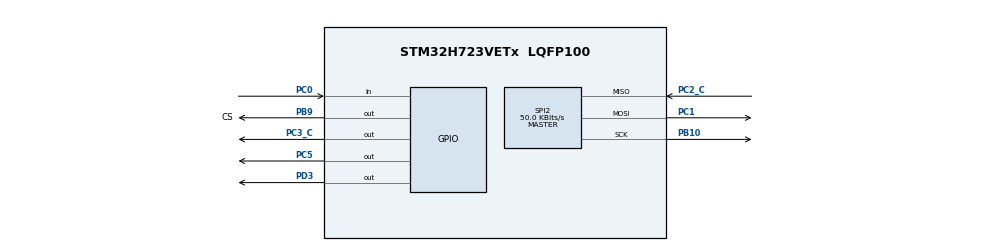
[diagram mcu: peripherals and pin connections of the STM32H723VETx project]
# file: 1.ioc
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CORTEX_M7.default_mode_Activation=1
Mcu.Family=STM32H7
Mcu.Name=STM32H723VETx
Mcu.Package=LQFP100
NVIC.PriorityGroup=NVIC_PRIORITYGROUP_4
NVIC.SPI2_IRQn=true\:0\:0\:false\:false\:true\:true\:true\:true
PB10.GPIO_PuPd=GPIO_PULLDOWN
PB10.GPIO_Speed=GPIO_SPEED_FREQ_HIGH
PB10.Mode=Full_Duplex_Master
PB10.Signal=SPI2_SCK
PB9.GPIO_Label=CS
PB9.GPIO_ModeDefaultOutputPP=GPIO_MODE_OUTPUT_PP
PB9.GPIO_PuPd=GPIO_PULLDOWN
PB9.GPIO_Speed=GPIO_SPEED_FREQ_HIGH
PB9.PinState=GPIO_PIN_SET
PB9.Signal=GPIO_Output
PC0.Signal=GPIO_Input
PC1.GPIO_PuPd=GPIO_PULLDOWN
PC1.GPIO_Speed=GPIO_SPEED_FREQ_HIGH
PC1.Mode=Full_Duplex_Master
PC1.Signal=SPI2_MOSI
PC2_C.GPIO_PuPd=GPIO_PULLUP
PC2_C.GPIO_Speed=GPIO_SPEED_FREQ_HIGH
PC2_C.Mode=Full_Duplex_Master
PC2_C.Signal=SPI2_MISO
PC3_C.GPIO_PuPd=GPIO_PULLDOWN
PC3_C.Signal=GPIO_Output
PC5.GPIO_ModeDefaultOutputPP=GPIO_MODE_OUTPUT_PP
PC5.GPIO_PuPd=GPIO_PULLDOWN
PC5.Signal=GPIO_Output
PD3.PinState=GPIO_PIN_SET
PD3.Signal=GPIO_Output
PH0-OSC_IN.Mode=HSE-External-Oscillator
PH0-OSC_IN.Signal=RCC_OSC_IN
PH1-OSC_OUT.Mode=HSE-External-Oscillator
PH1-OSC_OUT.Signal=RCC_OSC_OUT
ProjectManager.HeapSize=0x200
ProjectManager.StackSize=0x400
ProjectManager.TargetToolchain=MDK-ARM V5.32
RCC.ADCFreq_Value=6400000
RCC.APB1Freq_Value=42500000
RCC.APB2Freq_Value=42500000
RCC.APB3Freq_Value=42500000
RCC.APB4Freq_Value=42500000
RCC.CortexFreq_Value=340000000
RCC.DIVM1=1
RCC.DIVM2=6
RCC.DIVN1=42
RCC.DIVN2=120
RCC.DIVP1=1
RCC.DIVP2=25
RCC.HCLKFreq_Value=42500000
RCC.HPRE=RCC_HCLK_DIV8
RCC.HSE_VALUE=8000000
RCC.PLL3FRACN=0
RCC.PLLFRACN=4096
RCC.PLLSourceVirtual=RCC_PLLSOURCE_HSE
RCC.SPI123CLockSelection=RCC_SPI123CLKSOURCE_PLL2
RCC.SYSCLKFreq_VALUE=340000000
RCC.SYSCLKSource=RCC_SYSCLKSOURCE_PLLCLK
RCC.USBFreq_Value=170000000
SPI2.BaudRatePrescaler=SPI_BAUDRATEPRESCALER_128
SPI2.CLKPhase=SPI_PHASE_2EDGE
SPI2.CLKPolarity=SPI_POLARITY_LOW
SPI2.CRCCalculation=SPI_CRCCALCULATION_DISABLE
SPI2.CalculateBaudRate=50.0 KBits/s
SPI2.DataSize=SPI_DATASIZE_8BIT
SPI2.Direction=SPI_DIRECTION_2LINES
SPI2.Mode=SPI_MODE_MASTER
SPI2.NSSPMode=SPI_NSS_PULSE_ENABLE
SPI2.VirtualType=VM_MASTER
board=custom

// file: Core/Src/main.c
/* USER CODE BEGIN Header */
/**
  ******************************************************************************
  * @file           : main.c
  * @brief          : Main program body
  ******************************************************************************
  * @attention
  *
  * Copyright (c) 2022 STMicroelectronics.
  * All rights reserved.
  *
  * This software is licensed under terms that can be found in the LICENSE file
  * in the root directory of this software component.
  * If no LICENSE file comes with this software, it is provided AS-IS.
  *
  ******************************************************************************
  */
/* USER CODE END Header */
#include "main.h"

/* USER CODE BEGIN Includes */
#include "CDD_L9963_drv_interface.h"
/* USER CODE END Includes */

SPI_HandleTypeDef hspi2;

void SystemClock_Config(void);
static void MPU_Config(void);
static void MX_GPIO_Init(void);
static void MX_SPI2_Init(void);

int main(void)
{

  /* MPU Configuration--------------------------------------------------------*/
  MPU_Config();

  /* MCU Configuration--------------------------------------------------------*/

  /* Reset of all peripherals, Initializes the Flash interface and the Systick. */
  HAL_Init();

  /* Configure the system clock */
  SystemClock_Config();

  /* Initialize all configured peripherals */
  MX_GPIO_Init();
  MX_SPI2_Init();
  /* USER CODE BEGIN 2 */
	HAL_GPIO_WritePin(GPIOB, GPIO_PIN_10, GPIO_PIN_RESET);

  /* USER CODE END 2 */

  /* Infinite loop */
  /* USER CODE BEGIN WHILE */
	uint8_t t = 0;
  L9963_Test_Init();
	//uint8_t return_code = true;
	//uint8 res = true;

	//L9963_SPI_Rx_Inst_t  *spi_rx;
	//spi_rx = 0;
	//uint8_t op_code[1] = {0xff};
	//HAL_GPIO_WritePin(GPIOB, GPIO_PIN_9, GPIO_PIN_RESET);

	uint8_t spi_mosi[5];

  while (1)
  {
		//uint8_t res = true;
    /* USER CODE END WHILE */

    /* USER CODE BEGIN 3 */

		//GCDD_L9963_CellVol_Burst_Read();
		//L9963_SPI_Rx_Inst_t spi_rx_t;

		//L9963_SPI_CS_SELECT;

		//HAL_SPI_Transmit(&hspi2,&t,1,100);

		//L9963_SPI_CS_UNSELECT;

//		//	L9963_SPI_CS_SELECT;
//
//		//res = 	HAL_SPI_TransmitReceive( &hspi2, &spi_mosi[0], (((uint8 *) spi_rx) ), 5,  100);
//
//	//	GCDD_L9963_TxData(&spi_mosi[0], (((uint8 *) spi_rx) ), 5);
//
//		L9963_SPI_CS_UNSELECT;
//	HAL_Delay(319); /*Total Delay time need to be 219us */
//	L9963_SPI_CS_SELECT;
//		//	HAL_SPI_TransmitReceive( &hspi2, &spi_mosi[0], (((uint8 *) spi_rx) ), 5,  100);
//		HAL_SPI_Transmit(&hspi2, spi_mosi,5,100);
//
//		L9963_SPI_CS_UNSELECT;
//	HAL_Delay(319);
//	spi_mosi[0] = 0xC0; /*first 24 bit is reseved*/
//	spi_mosi[1] = 0x04;
//	spi_mosi[2] = 0x0F;
//	spi_mosi[3] = 0x00;
//	spi_mosi[4] = 0x28;
//
//		L9963_SPI_CS_SELECT;
//		//	HAL_SPI_TransmitReceive( &hspi2, &spi_mosi[0], (((uint8 *) spi_rx) ), 5,  100);
//			HAL_SPI_Transmit(&hspi2, spi_mosi,5,100);
//	L9963_SPI_CS_UNSELECT;
//	HAL_Delay(2519); /*Total Delay time need to be 219us */
//
   // Delay(6517);
//		//uint8 return_code = true;'
//	//	return_code &= L9963_Single_Read(GEN_STATUS_ADD, 0xD, &spi_rx_t);

//
//
		//HAL_Delay(50);

	/////////////////////ģ��////////////////////////////////
	//	uint8_t spi_mosi[5];
//	spi_mosi[0] = 0x82; /*first 24 bit is reseved*/
//	  spi_mosi[1] = 0x04;
//	  spi_mosi[2] = 0x00;
//	  spi_mosi[3] = 0x00;
//	  spi_mosi[4] = 0x17;
//
//		Delay(2000);
//
//		L9963_SPI_CS_SELECT;
//			HAL_SPI_Transmit(&hspi2,&spi_mosi[0],5,100);
//L9963_SPI_CS_UNSELECT;
//
//	Delay(819);
//
//		L9963_SPI_CS_SELECT;
//			HAL_SPI_Transmit(&hspi2,&spi_mosi[0],5,100);
//L9963_SPI_CS_UNSELECT;
//	Delay(819);
//
//
//
//
//	Delay(4590);
//
//
//
//		L9963_SPI_CS_SELECT;
//			HAL_SPI_Transmit(&hspi2,&spi_mosi[0],5,100);
//L9963_SPI_CS_UNSELECT;
//
//	Delay(319);
//
//	L9963_SPI_CS_SELECT;
//			HAL_SPI_Transmit(&hspi2,&spi_mosi[0],5,100);
//L9963_SPI_CS_UNSELECT;
//	Delay(319);
//
//
//	Delay(6590);
//
//	  spi_mosi[0] = 0xC0; /*first 24 bit is reseved*/
//	  spi_mosi[1] = 0x04;
//	  spi_mosi[2] = 0x0F;
//	  spi_mosi[3] = 0x00;
//	  spi_mosi[4] = 0x28;
//
//
//	    L9963_SPI_CS_SELECT;
//			HAL_SPI_Transmit(&hspi2,&spi_mosi[0],5,100);
//      L9963_SPI_CS_UNSELECT;
//
//	//Delay(319);
//	Delay(2519);
//	  spi_mosi[0] = 0xC2; /*first 24 bit is reseved*/
//	  spi_mosi[1] = 0x0C;
//	  spi_mosi[2] = 0x00;
//	  spi_mosi[3] = 0x00;
//	  spi_mosi[4] = 0x0C;
//
//	L9963_SPI_CS_SELECT;
//			HAL_SPI_Transmit(&hspi2,&spi_mosi[0],5,100);
//L9963_SPI_CS_UNSELECT;
//
//	//Delay(319);
//	Delay(2519);
//
//
//	  spi_mosi[0] = 0x82; /*first 24 bit is reseved*/
//	  spi_mosi[1] = 0x04;
//	  spi_mosi[2] = 0x00;
//	  spi_mosi[3] = 0x00;
//	  spi_mosi[4] = 0x17;
//
//
//
//	L9963_SPI_CS_SELECT;
//			HAL_SPI_Transmit(&hspi2,&spi_mosi[0],5,100);
//L9963_SPI_CS_UNSELECT;
//
//	Delay(319);
//	Delay(2519);
//
//	L9963_SPI_CS_SELECT;
//			HAL_SPI_Transmit(&hspi2,&spi_mosi[0],5,100);
//L9963_SPI_CS_UNSELECT;
//
//	Delay(319);
//		Delay(2519);
//
//
//
//			Delay(65900);
//
			/////////////////////ģ��////////////////////////////////

	GCDD_L9963_CellVol_Burst_Read();

		//HAL_SPI_Transmit(&hspi2,&t,1,100);
  }
  /* USER CODE END 3 */
}

void SystemClock_Config(void)
{
  RCC_OscInitTypeDef RCC_OscInitStruct = {0};
  RCC_ClkInitTypeDef RCC_ClkInitStruct = {0};

  /** Supply configuration update enable
  */
  HAL_PWREx_ConfigSupply(PWR_LDO_SUPPLY);

  /** Configure the main internal regulator output voltage
  */
  __HAL_PWR_VOLTAGESCALING_CONFIG(PWR_REGULATOR_VOLTAGE_SCALE1);

  while(!__HAL_PWR_GET_FLAG(PWR_FLAG_VOSRDY)) {}

  /** Macro to configure the PLL clock source
  */
  __HAL_RCC_PLL_PLLSOURCE_CONFIG(RCC_PLLSOURCE_HSE);

  /** Initializes the RCC Oscillators according to the specified parameters
  * in the RCC_OscInitTypeDef structure.
  */
  RCC_OscInitStruct.OscillatorType = RCC_OSCILLATORTYPE_HSE;
  RCC_OscInitStruct.HSEState = RCC_HSE_ON;
  RCC_OscInitStruct.PLL.PLLState = RCC_PLL_ON;
  RCC_OscInitStruct.PLL.PLLSource = RCC_PLLSOURCE_HSE;
  RCC_OscInitStruct.PLL.PLLM = 1;
  RCC_OscInitStruct.PLL.PLLN = 42;
  RCC_OscInitStruct.PLL.PLLP = 1;
  RCC_OscInitStruct.PLL.PLLQ = 2;
  RCC_OscInitStruct.PLL.PLLR = 2;
  RCC_OscInitStruct.PLL.PLLRGE = RCC_PLL1VCIRANGE_3;
  RCC_OscInitStruct.PLL.PLLVCOSEL = RCC_PLL1VCOWIDE;
  RCC_OscInitStruct.PLL.PLLFRACN = 4096;
  if (HAL_RCC_OscConfig(&RCC_OscInitStruct) != HAL_OK)
  {
    Error_Handler();
  }

  /** Initializes the CPU, AHB and APB buses clocks
  */
  RCC_ClkInitStruct.ClockType = RCC_CLOCKTYPE_HCLK|RCC_CLOCKTYPE_SYSCLK
                              |RCC_CLOCKTYPE_PCLK1|RCC_CLOCKTYPE_PCLK2
                              |RCC_CLOCKTYPE_D3PCLK1|RCC_CLOCKTYPE_D1PCLK1;
  RCC_ClkInitStruct.SYSCLKSource = RCC_SYSCLKSOURCE_PLLCLK;
  RCC_ClkInitStruct.SYSCLKDivider = RCC_SYSCLK_DIV1;
  RCC_ClkInitStruct.AHBCLKDivider = RCC_HCLK_DIV8;
  RCC_ClkInitStruct.APB3CLKDivider = RCC_APB3_DIV1;
  RCC_ClkInitStruct.APB1CLKDivider = RCC_APB1_DIV1;
  RCC_ClkInitStruct.APB2CLKDivider = RCC_APB2_DIV1;
  RCC_ClkInitStruct.APB4CLKDivider = RCC_APB4_DIV1;

  if (HAL_RCC_ClockConfig(&RCC_ClkInitStruct, FLASH_LATENCY_0) != HAL_OK)
  {
    Error_Handler();
  }
}

static void MX_SPI2_Init(void)
{

  /* USER CODE BEGIN SPI2_Init 1 */

//	hspi2.Init.CRCCalculation = SPI_CRCCALCULATION_ENABLE;
//	hspi2.Init.CRCLength = SPI_CRC_LENGTH_6BIT;
//  hspi2.Init.CRCPolynomial = 0x59;
//
  /* USER CODE END SPI2_Init 1 */
  /* SPI2 parameter configuration*/
  hspi2.Instance = SPI2;
  hspi2.Init.Mode = SPI_MODE_MASTER;
  hspi2.Init.Direction = SPI_DIRECTION_2LINES;
  hspi2.Init.DataSize = SPI_DATASIZE_8BIT;
  hspi2.Init.CLKPolarity = SPI_POLARITY_LOW;
  hspi2.Init.CLKPhase = SPI_PHASE_2EDGE;
  hspi2.Init.NSS = SPI_NSS_SOFT;
  hspi2.Init.BaudRatePrescaler = SPI_BAUDRATEPRESCALER_128;
  hspi2.Init.FirstBit = SPI_FIRSTBIT_MSB;
  hspi2.Init.TIMode = SPI_TIMODE_DISABLE;
  hspi2.Init.CRCCalculation = SPI_CRCCALCULATION_DISABLE;
  hspi2.Init.CRCPolynomial = 0x0;
  hspi2.Init.NSSPMode = SPI_NSS_PULSE_ENABLE;
  hspi2.Init.NSSPolarity = SPI_NSS_POLARITY_LOW;
  hspi2.Init.FifoThreshold = SPI_FIFO_THRESHOLD_01DATA;
  hspi2.Init.TxCRCInitializationPattern = SPI_CRC_INITIALIZATION_ALL_ZERO_PATTERN;
  hspi2.Init.RxCRCInitializationPattern = SPI_CRC_INITIALIZATION_ALL_ZERO_PATTERN;
  hspi2.Init.MasterSSIdleness = SPI_MASTER_SS_IDLENESS_00CYCLE;
  hspi2.Init.MasterInterDataIdleness = SPI_MASTER_INTERDATA_IDLENESS_00CYCLE;
  hspi2.Init.MasterReceiverAutoSusp = SPI_MASTER_RX_AUTOSUSP_DISABLE;
  hspi2.Init.MasterKeepIOState = SPI_MASTER_KEEP_IO_STATE_DISABLE;
  hspi2.Init.IOSwap = SPI_IO_SWAP_DISABLE;
  if (HAL_SPI_Init(&hspi2) != HAL_OK)
  {
    Error_Handler();
  }

}

static void MX_GPIO_Init(void)
{
  GPIO_InitTypeDef GPIO_InitStruct = {0};

  /* GPIO Ports Clock Enable */
  __HAL_RCC_GPIOH_CLK_ENABLE();
  __HAL_RCC_GPIOC_CLK_ENABLE();
  __HAL_RCC_GPIOB_CLK_ENABLE();
  __HAL_RCC_GPIOD_CLK_ENABLE();

  /*Configure GPIO pin Output Level */
  HAL_GPIO_WritePin(GPIOC, GPIO_PIN_3|GPIO_PIN_5, GPIO_PIN_RESET);

  /*Configure GPIO pin Output Level */
  HAL_GPIO_WritePin(GPIOD, GPIO_PIN_3, GPIO_PIN_SET);

  /*Configure GPIO pin Output Level */
  HAL_GPIO_WritePin(CS_GPIO_Port, CS_Pin, GPIO_PIN_SET);

  /*Configure GPIO pin : PC0 */
  GPIO_InitStruct.Pin = GPIO_PIN_0;
  GPIO_InitStruct.Mode = GPIO_MODE_INPUT;
  GPIO_InitStruct.Pull = GPIO_NOPULL;
  HAL_GPIO_Init(GPIOC, &GPIO_InitStruct);

  /*Configure GPIO pins : PC3 PC5 */
  GPIO_InitStruct.Pin = GPIO_PIN_3|GPIO_PIN_5;
  GPIO_InitStruct.Mode = GPIO_MODE_OUTPUT_PP;
  GPIO_InitStruct.Pull = GPIO_PULLDOWN;
  GPIO_InitStruct.Speed = GPIO_SPEED_FREQ_LOW;
  HAL_GPIO_Init(GPIOC, &GPIO_InitStruct);

  /*Configure GPIO pin : PD3 */
  GPIO_InitStruct.Pin = GPIO_PIN_3;
  GPIO_InitStruct.Mode = GPIO_MODE_OUTPUT_PP;
  GPIO_InitStruct.Pull = GPIO_NOPULL;
  GPIO_InitStruct.Speed = GPIO_SPEED_FREQ_LOW;
  HAL_GPIO_Init(GPIOD, &GPIO_InitStruct);

  /*Configure GPIO pin : CS_Pin */
  GPIO_InitStruct.Pin = CS_Pin;
  GPIO_InitStruct.Mode = GPIO_MODE_OUTPUT_PP;
  GPIO_InitStruct.Pull = GPIO_PULLDOWN;
  GPIO_InitStruct.Speed = GPIO_SPEED_FREQ_HIGH;
  HAL_GPIO_Init(CS_GPIO_Port, &GPIO_InitStruct);

}

/* MPU Configuration */

void MPU_Config(void)
{
  MPU_Region_InitTypeDef MPU_InitStruct = {0};

  /* Disables the MPU */
  HAL_MPU_Disable();

  /** Initializes and configures the Region and the memory to be protected
  */
  MPU_InitStruct.Enable = MPU_REGION_ENABLE;
  MPU_InitStruct.Number = MPU_REGION_NUMBER0;
  MPU_InitStruct.BaseAddress = 0x0;
  MPU_InitStruct.Size = MPU_REGION_SIZE_4GB;
  MPU_InitStruct.SubRegionDisable = 0x87;
  MPU_InitStruct.TypeExtField = MPU_TEX_LEVEL0;
  MPU_InitStruct.AccessPermission = MPU_REGION_NO_ACCESS;
  MPU_InitStruct.DisableExec = MPU_INSTRUCTION_ACCESS_DISABLE;
  MPU_InitStruct.IsShareable = MPU_ACCESS_SHAREABLE;
  MPU_InitStruct.IsCacheable = MPU_ACCESS_NOT_CACHEABLE;
  MPU_InitStruct.IsBufferable = MPU_ACCESS_NOT_BUFFERABLE;

  HAL_MPU_ConfigRegion(&MPU_InitStruct);
  /* Enables the MPU */
  HAL_MPU_Enable(MPU_PRIVILEGED_DEFAULT);

}

void Error_Handler(void)
{
  __disable_irq();
  while (1)
  {
  }
}
